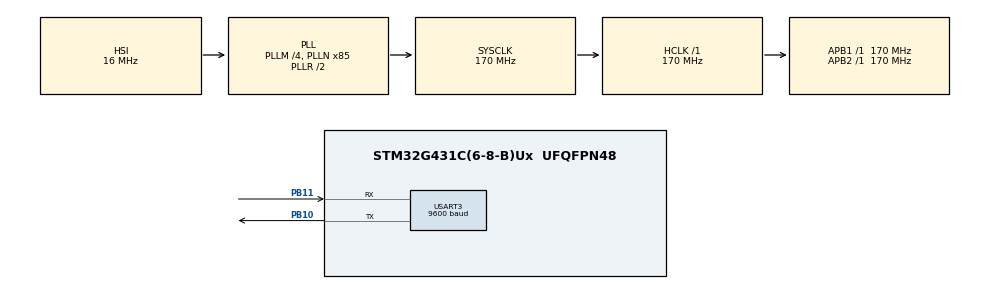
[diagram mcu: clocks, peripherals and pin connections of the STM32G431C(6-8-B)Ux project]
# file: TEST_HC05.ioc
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Mcu.Family=STM32G4
Mcu.Name=STM32G431C(6-8-B)Ux
Mcu.Package=UFQFPN48
NVIC.PriorityGroup=NVIC_PRIORITYGROUP_4
NVIC.USART3_IRQn=true\:0\:0\:false\:false\:true\:true\:true\:true
PB10.Mode=Asynchronous
PB10.Signal=USART3_TX
PB11.Mode=Asynchronous
PB11.Signal=USART3_RX
ProjectManager.HeapSize=0x200
ProjectManager.StackSize=0x400
ProjectManager.TargetToolchain=STM32CubeIDE
RCC.ADC12Freq_Value=170000000
RCC.AHBFreq_Value=170000000
RCC.APB1Freq_Value=170000000
RCC.APB1TimFreq_Value=170000000
RCC.APB2Freq_Value=170000000
RCC.APB2TimFreq_Value=170000000
RCC.CortexFreq_Value=170000000
RCC.EXTERNAL_CLOCK_VALUE=12288000
RCC.HCLKFreq_Value=170000000
RCC.HSE_VALUE=8000000
RCC.HSI48_VALUE=48000000
RCC.HSI_VALUE=16000000
RCC.LSE_VALUE=32768
RCC.PLLM=RCC_PLLM_DIV4
RCC.PLLN=85
RCC.SYSCLKFreq_VALUE=170000000
RCC.SYSCLKSource=RCC_SYSCLKSOURCE_PLLCLK
RCC.USBFreq_Value=170000000
RCC.VCOOutputFreq_Value=340000000
USART3.BaudRate=9600
USART3.VirtualMode-Asynchronous=VM_ASYNC
VP_SYS_VS_DBSignals.Mode=DisableDeadBatterySignals
board=custom

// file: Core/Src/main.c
/* USER CODE BEGIN Header */
/**
  ******************************************************************************
  * @file           : main.c
  * @brief          : Main program body
  ******************************************************************************
  * @attention
  *
  * Copyright (c) 2025 STMicroelectronics.
  * All rights reserved.
  *
  * This software is licensed under terms that can be found in the LICENSE file
  * in the root directory of this software component.
  * If no LICENSE file comes with this software, it is provided AS-IS.
  *
  ******************************************************************************
  */
/* USER CODE END Header */
#include "main.h"
#include "hc05_usart.h"

UART_HandleTypeDef huart3;

void SystemClock_Config(void);
static void MX_GPIO_Init(void);
static void MX_USART3_UART_Init(void);

int main(void)
{

  /* MCU Configuration--------------------------------------------------------*/

  /* Reset of all peripherals, Initializes the Flash interface and the Systick. */
  HAL_Init();

  /* Configure the system clock */
  SystemClock_Config();

  /* Initialize all configured peripherals */
  MX_GPIO_Init();
  MX_USART3_UART_Init();
  /* USER CODE BEGIN 2 */
  HC05_Init(9600); // 9600 est le BaudRate par défaut pour la communication de données

      char tx_buffer[] = "Bonjour HC-05!\r\n";
      char rx_buffer[32]; // Tampon de 32 caractères
  /* USER CODE END 2 */

  /* Infinite loop */
  /* USER CODE BEGIN WHILE */
  while (1)
  {// 1. ENVOI
      HC05_SendString(tx_buffer);
      HAL_Delay(1000); // Attendre 1 seconde avant d'envoyer à nouveau

      if (HC05_ReceiveString(rx_buffer, 10, 500) == HAL_OK)
      {
        HC05_SendString("ECHO: ");      // Envoie un préfixe pour identifier l'écho
          HC05_SendString(rx_buffer);     // Envoie la chaîne reçue
          HC05_SendString("\r\n");        // Ajoute un retour à la ligne pour la lisibilité

      }
    /* USER CODE END WHILE */

  }
}

void SystemClock_Config(void)
{
  RCC_OscInitTypeDef RCC_OscInitStruct = {0};
  RCC_ClkInitTypeDef RCC_ClkInitStruct = {0};

  /** Configure the main internal regulator output voltage
  */
  HAL_PWREx_ControlVoltageScaling(PWR_REGULATOR_VOLTAGE_SCALE1_BOOST);

  /** Initializes the RCC Oscillators according to the specified parameters
  * in the RCC_OscInitTypeDef structure.
  */
  RCC_OscInitStruct.OscillatorType = RCC_OSCILLATORTYPE_HSI;
  RCC_OscInitStruct.HSIState = RCC_HSI_ON;
  RCC_OscInitStruct.HSICalibrationValue = RCC_HSICALIBRATION_DEFAULT;
  RCC_OscInitStruct.PLL.PLLState = RCC_PLL_ON;
  RCC_OscInitStruct.PLL.PLLSource = RCC_PLLSOURCE_HSI;
  RCC_OscInitStruct.PLL.PLLM = RCC_PLLM_DIV4;
  RCC_OscInitStruct.PLL.PLLN = 85;
  RCC_OscInitStruct.PLL.PLLP = RCC_PLLP_DIV2;
  RCC_OscInitStruct.PLL.PLLQ = RCC_PLLQ_DIV2;
  RCC_OscInitStruct.PLL.PLLR = RCC_PLLR_DIV2;
  if (HAL_RCC_OscConfig(&RCC_OscInitStruct) != HAL_OK)
  {
    Error_Handler();
  }

  /** Initializes the CPU, AHB and APB buses clocks
  */
  RCC_ClkInitStruct.ClockType = RCC_CLOCKTYPE_HCLK|RCC_CLOCKTYPE_SYSCLK
                              |RCC_CLOCKTYPE_PCLK1|RCC_CLOCKTYPE_PCLK2;
  RCC_ClkInitStruct.SYSCLKSource = RCC_SYSCLKSOURCE_PLLCLK;
  RCC_ClkInitStruct.AHBCLKDivider = RCC_SYSCLK_DIV1;
  RCC_ClkInitStruct.APB1CLKDivider = RCC_HCLK_DIV1;
  RCC_ClkInitStruct.APB2CLKDivider = RCC_HCLK_DIV1;

  if (HAL_RCC_ClockConfig(&RCC_ClkInitStruct, FLASH_LATENCY_4) != HAL_OK)
  {
    Error_Handler();
  }
}

static void MX_USART3_UART_Init(void)
{

  huart3.Instance = USART3;
  huart3.Init.BaudRate = 9600;
  huart3.Init.WordLength = UART_WORDLENGTH_8B;
  huart3.Init.StopBits = UART_STOPBITS_1;
  huart3.Init.Parity = UART_PARITY_NONE;
  huart3.Init.Mode = UART_MODE_TX_RX;
  huart3.Init.HwFlowCtl = UART_HWCONTROL_NONE;
  huart3.Init.OverSampling = UART_OVERSAMPLING_16;
  huart3.Init.OneBitSampling = UART_ONE_BIT_SAMPLE_DISABLE;
  huart3.Init.ClockPrescaler = UART_PRESCALER_DIV1;
  huart3.AdvancedInit.AdvFeatureInit = UART_ADVFEATURE_NO_INIT;
  if (HAL_UART_Init(&huart3) != HAL_OK)
  {
    Error_Handler();
  }
  if (HAL_UARTEx_SetTxFifoThreshold(&huart3, UART_TXFIFO_THRESHOLD_1_8) != HAL_OK)
  {
    Error_Handler();
  }
  if (HAL_UARTEx_SetRxFifoThreshold(&huart3, UART_RXFIFO_THRESHOLD_1_8) != HAL_OK)
  {
    Error_Handler();
  }
  if (HAL_UARTEx_DisableFifoMode(&huart3) != HAL_OK)
  {
    Error_Handler();
  }

}

static void MX_GPIO_Init(void)
{

  /* GPIO Ports Clock Enable */
  __HAL_RCC_GPIOB_CLK_ENABLE();

}

void Error_Handler(void)
{
  __disable_irq();
  while (1)
  {
  }
}
